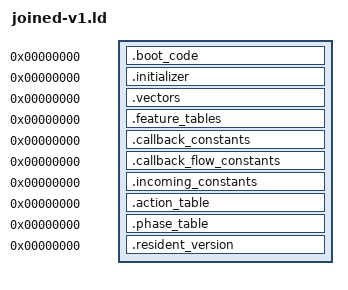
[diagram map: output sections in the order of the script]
OUTPUT_ARCH(riscv)
SECTIONS
{
 .boot_code 0 : SUBALIGN(2) { *(.boot_code)
  *(.text.tsl9_feature_state_records_provider_1056e)
  *(.text.tsl9_feature_state_records_block_1057e)
  *(.text.tsl9_feature_state_records_block_10586)
  *(.text.tsl9_feature_state_records_block_1058c)
  *(.text.tsl9_feature_state_records_block_10594)
  *(.text.tsl9_feature_state_records_block_10598)
  *(.text.tsl9_feature_state_records_provider_1059c)
  *(.text.tsl9_feature_state_records_block_105a2)
  *(.text.tsl9_feature_state_records_block_105a8)
  *(.text.tsl9_feature_state_records_block_105ae)
  *(.text.tsl9_feature_state_records_block_105b4)
  *(.text.tsl9_feature_state_records_block_105bc)
  *(.text.tsl9_feature_state_records_block_105c0)
  *(.text.tsl9_feature_state_records_provider_105c4)
  *(.text.tsl9_feature_state_records_provider_105d0)
  *(.text.tsl9_feature_state_records_block_105d6)
  *(.text.tsl9_feature_state_records_block_105dc)
  *(.text.tsl9_feature_state_records_block_105e4)
  *(.text.tsl9_feature_state_records_block_105e8)
  *(.text.tsl9_feature_state_records_provider_105ec)
  *(.text.tsl9_feature_state_records_block_105f6)
  *(.text.tsl9_feature_state_records_block_10606)
  *(.text.tsl9_feature_state_records_block_1060e)
  *(.text.tsl9_feature_state_records_block_10618)
  *(.text.tsl9_feature_state_records_block_1061a)
  *(.text.tsl9_feature_state_records_provider_106c0)
  *(.text.tsl9_feature_state_records_block_106ce)
  *(.text.tsl9_feature_state_records_block_106de)
  *(.text.tsl9_feature_state_records_provider_106e0)
  *(.text.tsl9_feature_state_records_provider_107c6)
  *(.text.tsl9_feature_state_records_block_107d8)
  *(.text.tsl9_feature_state_records_block_107da)
  *(.text.tsl9_feature_state_records_block_107ea)
  *(.text.tsl9_feature_state_records_block_107ee)
  *(.text.tsl9_feature_state_records_block_107f8)
  *(.text.tsl9_feature_state_records_block_10802)
  *(.text.tsl9_feature_state_records_block_10810)
  *(.text.tsl9_feature_external_10870)
  *(.text.tsl9_feature_state_records_block_10880)
  *(.text.tsl9_feature_state_records_block_10886)
  *(.text.tsl9_feature_state_records_block_1088c)
  *(.text.tsl9_feature_state_records_block_10890)
  *(.text.tsl9_feature_state_records_block_1089c)
  *(.text.tsl9_feature_state_records_block_108a0)
  *(.text.tsl9_feature_state_records_block_108b4)
  *(.text.tsl9_feature_state_records_block_108c0)
  *(.text.tsl9_feature_state_records_block_108c6)
  *(.text.tsl9_feature_state_records_block_108cc)
  *(.text.tsl9_feature_state_records_block_108d2)
  *(.text.tsl9_feature_external_108d8)
  *(.text.tsl9_feature_state_records_block_108ee)
  *(.text.tsl9_feature_state_records_block_108f0)
  *(.text.tsl9_feature_state_records_block_108fa)
  *(.text.tsl9_feature_state_records_block_1092e)
  *(.text.tsl9_feature_external_10936)
  *(.text.tsl9_feature_external_10944)
  *(.text.tsl9_feature_state_records_block_1095a)
  *(.text.tsl9_feature_state_records_block_1095c)
  *(.text.tsl9_feature_state_records_block_10966)
  *(.text.tsl9_feature_state_records_block_109bc)
  *(.text.tsl9_feature_external_109c4)
  *(.text.tsl9_feature_state_records_block_109da)
  *(.text.tsl9_feature_state_records_block_109dc)
  *(.text.tsl9_feature_state_records_block_109e6)
  *(.text.tsl9_feature_state_records_block_109f8)
  *(.text.tsl9_feature_external_10a00)
  *(.text.tsl9_feature_state_records_block_10a0a)
  *(.text.tsl9_feature_state_records_block_10a14)
  *(.text.tsl9_feature_external_10a16)
  *(.text.tsl9_feature_state_records_block_10a2c)
  *(.text.tsl9_feature_state_records_block_10a2e)
  *(.text.tsl9_feature_state_records_block_10a38)
  *(.text.tsl9_feature_state_records_block_10a5a)
  *(.text.tsl9_feature_state_records_block_10a72)
  *(.text.tsl9_feature_state_records_block_10a80)
  *(.text.tsl9_feature_state_records_block_10a86)
  *(.text.tsl9_feature_state_records_block_10a98)
  *(.text.tsl9_feature_state_records_block_10aa4)
  *(.text.tsl9_feature_state_records_block_10abe)
  *(.text.tsl9_feature_external_10ac6)
  *(.text.tsl9_feature_state_records_block_10ad4)
  *(.text.tsl9_feature_state_records_block_10ae2)
  *(.text.tsl9_feature_state_records_block_10af0)
  *(.text.tsl9_feature_state_records_block_10af8)
  *(.text.tsl9_feature_state_records_block_10b00)
  *(.text.tsl9_feature_state_records_block_10b04)
  *(.text.tsl9_feature_external_10b0a)
  *(.text.tsl9_feature_state_records_block_10b22)
  *(.text.tsl9_feature_state_records_block_10b30)
  *(.text.tsl9_feature_state_records_block_10b3a)
  *(.text.tsl9_feature_state_records_block_10b42)
  *(.text.tsl9_feature_state_records_block_10b4c)
  *(.text.tsl9_feature_state_records_block_10b56)
  *(.text.tsl9_feature_state_records_block_10b5a)
  *(.text.tsl9_feature_external_10b60)
  *(.text.tsl9_feature_state_records_block_10b6e)
  *(.text.tsl9_feature_state_records_block_10b72)
  *(.text.tsl9_feature_state_records_block_10b7a)
  *(.text.tsl9_feature_state_records_block_10b82)
  *(.text.tsl9_feature_state_records_block_10b84)
  *(.text.tsl9_feature_state_records_block_10b8c)
  *(.text.tsl9_feature_state_records_block_10b94)
  *(.text.tsl9_feature_state_records_block_10b9c)
  *(.text.tsl9_feature_state_records_block_10bae)
  *(.text.tsl9_feature_state_records_block_10bbe)
  *(.text.tsl9_feature_state_records_block_10bc2)
  *(.text.tsl9_feature_state_records_block_10bde)
  *(.text.tsl9_feature_state_records_block_10bf8)
  *(.text.tsl9_feature_state_records_block_10c0a)
  *(.text.tsl9_feature_state_records_block_10c1c)
  *(.text.tsl9_main_services_provider_10c1e)
  *(.text.tsl9_feature_state_records_block_10c34)
 }
 .initializer 0 : SUBALIGN(4) { *(.initializer) }
 .vectors 0 : SUBALIGN(4) { *(.vectors) }
 .feature_tables 0 : SUBALIGN(4) { *(.feature_tables) }
 .callback_constants 0 : SUBALIGN(4) { *(.callback_constants) }
 .callback_flow_constants 0 : SUBALIGN(4) { *(.callback_flow_constants) }
 .incoming_constants 0 : SUBALIGN(4) { *(.incoming_constants) }
 .action_table 0 : SUBALIGN(4) { *(.action_table) }
 .phase_table 0 : SUBALIGN(4) { *(.phase_table) }
 .resident_version 0 : SUBALIGN(4) { *(.resident_version) }
 /DISCARD/ : { *(.comment) *(.riscv.attributes) *(.llvm_addrsig) }
}
